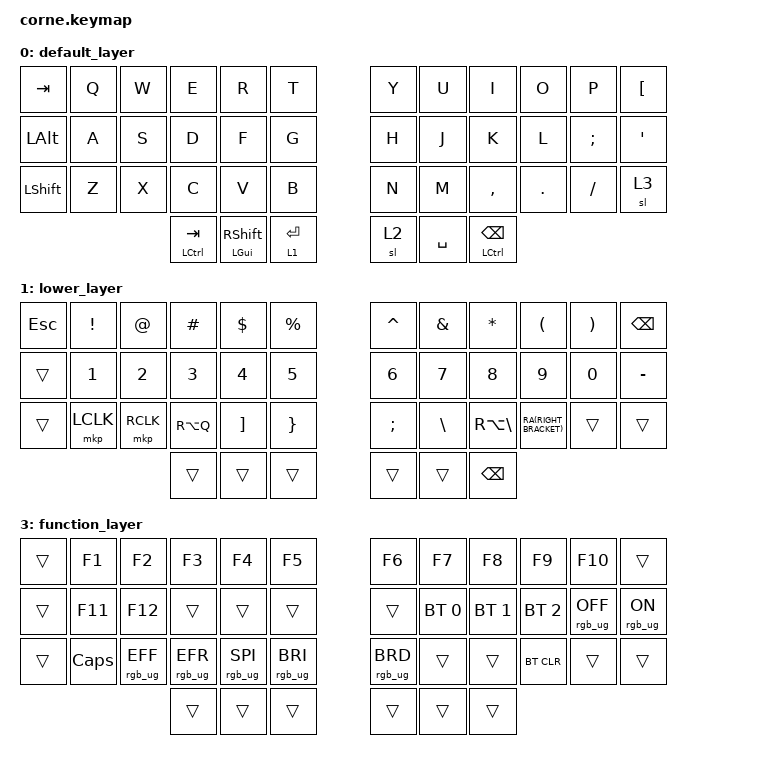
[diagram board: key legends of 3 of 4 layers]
/*
 * Copyright (c) 2020 The ZMK Contributors
 * Código copiado de um repositório genérico, que pretende ser uma fonte para forks
 * Fiz a cópia para que se pudesse utilizar no teclado do tupinikeebs
 * com o firmware padrão funcionou
 * SPDX-License-Identifier: MIT
 * copiei isso de um repositório genérico
 */


#include <behaviors.dtsi>
#include <dt-bindings/zmk/bt.h>
#include <dt-bindings/zmk/keys.h>
#include <dt-bindings/zmk/mouse.h>
#include <dt-bindings/zmk/rgb.h>


/ {
  behaviors {
    skq: sticky_key_quick_release {
      compatible = "zmk,behavior-sticky-key";
      label = "STICKY_KEY_QUICK_RELEASE";
      #binding-cells = <1>;
      bindings = <&kp>;
      release-after-ms = <1000>;
      quick-release;
    };
  };
};

/ {
    behaviors {
        rars:pressticky {
            compatible = "zmk,behavior-hold-tap";
            #binding-cells = <2>;
            flavor = "balanced";
            tapping-term-ms = <190>;
            bindings = <&kp>, <&skq>;
        };
    };
};


/ {
    combos { compatible = "zmk,combos"; };

    keymap {
        compatible = "zmk,keymap";

        default_layer {
            bindings = <
                &kp TAB      &kp Q   &kp W   &kp E   &kp R   &kp T          &kp Y   &kp U   &kp I      &kp O   &kp P      &kp LBKT
                &kp LALT     &kp A   &kp S   &kp D   &kp F   &kp G          &kp H   &kp J   &kp K      &kp L   &kp SEMI   &kp SINGLE_QUOTE
                &kp LSHIFT   &kp Z   &kp X   &kp C   &kp V   &kp B          &kp N   &kp M   &kp COMMA  &kp DOT &kp SLASH  &sl 3
               &mt LCTRL TAB   &rars LEFT_GUI RSHIFT   &lt 1 ENTER          &sl 2   &kp SPACE   &mt LCTRL BACKSPACE
            >;
        };

        lower_layer {
            bindings = <
&kp ESC &kp EXCL         &kp AT_SIGN   &kp POUND     &kp DOLLAR        &kp PERCENT         &kp CARET        &kp AMPERSAND      &kp ASTERISK  &kp LEFT_PARENTHESIS  &kp RIGHT_PARENTHESIS  &kp BSPC
&trans  &kp NUMBER_1     &kp NUMBER_2  &kp NUMBER_3  &kp NUMBER_4      &kp NUMBER_5        &kp NUMBER_6     &kp NUMBER_7       &kp NUMBER_8  &kp NUMBER_9          &kp NUMBER_0           &kp MINUS
&trans  &mkp LCLK        &mkp RCLK     &kp RA(Q)     &kp RIGHT_BRACKET &kp RIGHT_BRACE     &kp SEMI         &kp BSLH           &kp RA(BSLH)  &RA(RIGHT_BRACKET)    &trans                 &trans
                                       &trans        &trans            &trans              &trans           &trans             &kp BACKSPACE
            >;
        };

       
        raise_layer {
            bindings = <
                &kp TAB    &kp RA(Q)       &kp RA(W)       &kp UP      &kp MINUS    &kp PLUS             &kp &kp LBKT          &kp LS(LBKT)          &kp HOME    &kp PGUP             &kp RA(EQUAL)    &kp DELETE
                &trans     &kp LS(GRAVE)   &kp LEFT        &kp DOWN    &kp RIGHT    &kp EQUAL            &kp SINGLE_QUOTE      &kp LS(SINGLE_QUOTE)  &kp END     &kp PGDN             &kp GRAVE        &trans      
                &trans     &kp NUBS        &kp UNDERSCORE  &kp K_COPY  &kp K_PASTE  &kp LS(NUBS)         &kp C_PLAY_PAUSE      &kp C_PREVIOUS        &kp C_NEXT  &kp C_VOLUME_DOWN    &kp C_VOLUME_UP  &trans
                                                           &trans      &kp LSHIFT   &trans               &trans                &trans                &trans
            >;
        };

        function_layer {
            bindings = <
                &trans   &kp F1     &kp F2            &kp F3            &kp F4            &kp F5            &kp F6            &kp F7         &kp F8         &kp F9         &kp F10           &trans
                &trans   &kp F11    &kp F12           &trans            &trans            &trans            &trans            &bt BT_SEL 0   &bt BT_SEL 1   &bt BT_SEL 2   &rgb_ug RGB_OFF   &rgb_ug RGB_ON
                &trans   &kp CAPS   &rgb_ug RGB_EFF   &rgb_ug RGB_EFR   &rgb_ug RGB_SPI   &rgb_ug RGB_BRI   &rgb_ug RGB_BRD   &trans         &trans         &bt BT_CLR     &trans            &trans
                                                                    &trans     &trans     &trans            &trans     &trans     &trans
            >;
        };
    };
};

